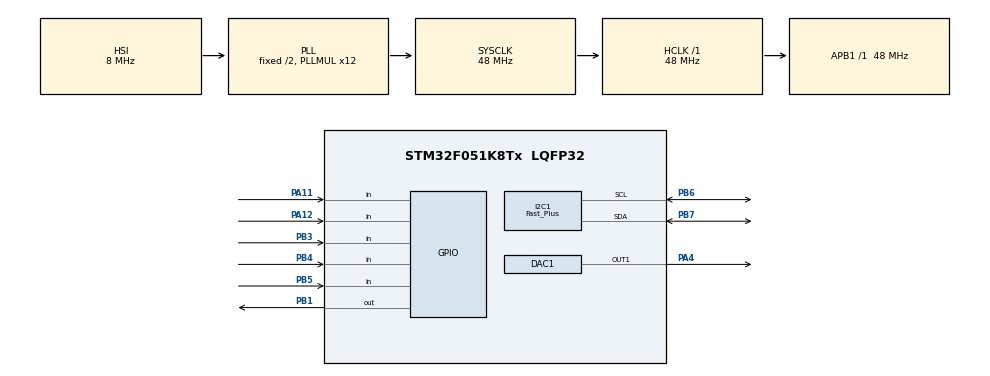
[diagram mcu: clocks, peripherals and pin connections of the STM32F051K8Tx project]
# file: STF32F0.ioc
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DAC1.DAC_Trigger=DAC_TRIGGER_T6_TRGO
Dma.DAC1_CH1.0.Direction=DMA_MEMORY_TO_PERIPH
Dma.DAC1_CH1.0.Instance=DMA1_Channel3
Dma.DAC1_CH1.0.MemDataAlignment=DMA_MDATAALIGN_HALFWORD
Dma.DAC1_CH1.0.MemInc=DMA_MINC_ENABLE
Dma.DAC1_CH1.0.Mode=DMA_CIRCULAR
Dma.DAC1_CH1.0.PeriphDataAlignment=DMA_PDATAALIGN_HALFWORD
Dma.DAC1_CH1.0.PeriphInc=DMA_PINC_DISABLE
Dma.DAC1_CH1.0.Priority=DMA_PRIORITY_LOW
Dma.Request0=DAC1_CH1
I2C1.Analog_Filter=I2C_ANALOGFILTER_DISABLE
I2C1.I2C_Speed_Mode=I2C_Fast_Plus
I2C1.Timing=0x00000002
Mcu.Family=STM32F0
Mcu.Name=STM32F051K8Tx
Mcu.Package=LQFP32
NVIC.DMA1_Channel2_3_IRQn=true\:0\:0\:false\:false\:true\:false\:true
NVIC.TIM14_IRQn=true\:0\:0\:false\:false\:true\:true\:true
NVIC.TIM6_DAC_IRQn=true\:0\:0\:false\:false\:true\:true\:true
PA11.GPIO_PuPd=GPIO_PULLUP
PA11.Signal=GPIO_Input
PA12.GPIO_PuPd=GPIO_PULLUP
PA12.Signal=GPIO_Input
PA13.Mode=Serial_Wire
PA13.Signal=SYS_SWDIO
PA14.Mode=Serial_Wire
PA14.Signal=SYS_SWCLK
PA4.Signal=COMP_DAC11_group
PB1.Signal=GPIO_Output
PB3.GPIO_PuPd=GPIO_PULLUP
PB3.Signal=GPIO_Input
PB4.GPIO_PuPd=GPIO_PULLUP
PB4.Signal=GPIO_Input
PB5.GPIO_PuPd=GPIO_PULLUP
PB5.Signal=GPIO_Input
PB6.GPIO_FM6=SYSCFG_CFGR1_I2C_FMP_PB6
PB6.GPIO_PuPdOD=GPIO_PULLUP
PB6.GPIO_Speed=GPIO_SPEED_FREQ_HIGH
PB6.Mode=I2C
PB6.Signal=I2C1_SCL
PB7.GPIO_FM7=SYSCFG_CFGR1_I2C_FMP_PB7
PB7.Mode=I2C
PB7.Signal=I2C1_SDA
PF0-OSC_IN.Mode=HSE-External-Oscillator
PF0-OSC_IN.Signal=RCC_OSC_IN
PF1-OSC_OUT.Mode=HSE-External-Oscillator
PF1-OSC_OUT.Signal=RCC_OSC_OUT
ProjectManager.HeapSize=0x200
ProjectManager.StackSize=0x400
ProjectManager.TargetToolchain=MDK-ARM V5
RCC.AHBFreq_Value=48000000
RCC.APB1Freq_Value=48000000
RCC.APB1TimFreq_Value=48000000
RCC.HCLKFreq_Value=48000000
RCC.PLLMUL=RCC_PLL_MUL12
RCC.SYSCLKFreq_VALUE=48000000
RCC.SYSCLKSource=RCC_SYSCLKSOURCE_PLLCLK
SH.COMP_DAC11_group.0=DAC1_OUT1,DAC_OUT1
TIM14.Period=1
TIM14.Prescaler=1
TIM6.Period=99
TIM6.TIM_MasterOutputTrigger=TIM_TRGO_UPDATE
VP_TIM14_VS_ClockSourceINT.Mode=Enable_Timer
VP_TIM6_VS_ClockSourceINT.Mode=Enable_Timer
board=custom

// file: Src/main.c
/* USER CODE BEGIN Header */
/**
  ******************************************************************************
  * @file           : main.c
  * @brief          : Main program body
  ******************************************************************************
  * @attention
  *
  * <h2><center>&copy; Copyright (c) 2019 STMicroelectronics.
  * All rights reserved.</center></h2>
  *
  * This software component is licensed by ST under BSD 3-Clause license,
  * the "License"; You may not use this file except in compliance with the
  * License. You may obtain a copy of the License at:
  *                        opensource.org/licenses/BSD-3-Clause
  *
  ******************************************************************************
  */
/* USER CODE END Header */

#include "main.h"

/* USER CODE BEGIN Includes */
#include "ssd1306.h"
#include "oscillator.h"
/* USER CODE END Includes */

DAC_HandleTypeDef hdac1;
DMA_HandleTypeDef hdma_dac1_ch1;

I2C_HandleTypeDef hi2c1;

TIM_HandleTypeDef htim6;
TIM_HandleTypeDef htim14;

/* USER CODE BEGIN PV */
char cfreq[7];
/* USER CODE END PV */

void SystemClock_Config(void);
static void MX_GPIO_Init(void);
static void MX_DMA_Init(void);
static void MX_DAC1_Init(void);
static void MX_I2C1_Init(void);
static void MX_TIM6_Init(void);
static void MX_TIM14_Init(void);

int main(void)
{

  /* MCU Configuration--------------------------------------------------------*/

  /* Reset of all peripherals, Initializes the Flash interface and the Systick. */
  HAL_Init();

  /* Configure the system clock */
  SystemClock_Config();

  /* Initialize all configured peripherals */
  MX_GPIO_Init();
  MX_DMA_Init();
  MX_DAC1_Init();
  MX_I2C1_Init();
  MX_TIM6_Init();
  MX_TIM14_Init();
  /* USER CODE BEGIN 2 */
			DAC_Osc_Init();
			HAL_GPIO_WritePin(GPIOB, GPIO_PIN_1, GPIO_PIN_SET);
			ssd1306_Init();
			ssd1306_Fill(0);
			ssd1306_SetCursor(0 ,0);
			ssd1306_WriteLogo(0);
			ssd1306_UpdateScreen();
			HAL_TIM_Base_Start_IT(&htim14);
  /* USER CODE END 2 */

  /* Infinite loop */
  while (1)
  {

  }
}

void SystemClock_Config(void)
{
  RCC_OscInitTypeDef RCC_OscInitStruct = {0};
  RCC_ClkInitTypeDef RCC_ClkInitStruct = {0};
  RCC_PeriphCLKInitTypeDef PeriphClkInit = {0};

  /** Initializes the CPU, AHB and APB busses clocks
  */
  RCC_OscInitStruct.OscillatorType = RCC_OSCILLATORTYPE_HSI;
  RCC_OscInitStruct.HSIState = RCC_HSI_ON;
  RCC_OscInitStruct.HSICalibrationValue = RCC_HSICALIBRATION_DEFAULT;
  RCC_OscInitStruct.PLL.PLLState = RCC_PLL_ON;
  RCC_OscInitStruct.PLL.PLLSource = RCC_PLLSOURCE_HSI;
  RCC_OscInitStruct.PLL.PLLMUL = RCC_PLL_MUL12;
  RCC_OscInitStruct.PLL.PREDIV = RCC_PREDIV_DIV1;
  if (HAL_RCC_OscConfig(&RCC_OscInitStruct) != HAL_OK)
  {
    Error_Handler();
  }
  /** Initializes the CPU, AHB and APB busses clocks
  */
  RCC_ClkInitStruct.ClockType = RCC_CLOCKTYPE_HCLK|RCC_CLOCKTYPE_SYSCLK
                              |RCC_CLOCKTYPE_PCLK1;
  RCC_ClkInitStruct.SYSCLKSource = RCC_SYSCLKSOURCE_PLLCLK;
  RCC_ClkInitStruct.AHBCLKDivider = RCC_SYSCLK_DIV1;
  RCC_ClkInitStruct.APB1CLKDivider = RCC_HCLK_DIV1;

  if (HAL_RCC_ClockConfig(&RCC_ClkInitStruct, FLASH_LATENCY_1) != HAL_OK)
  {
    Error_Handler();
  }
  PeriphClkInit.PeriphClockSelection = RCC_PERIPHCLK_I2C1;
  PeriphClkInit.I2c1ClockSelection = RCC_I2C1CLKSOURCE_HSI;
  if (HAL_RCCEx_PeriphCLKConfig(&PeriphClkInit) != HAL_OK)
  {
    Error_Handler();
  }
}

static void MX_DAC1_Init(void)
{

  DAC_ChannelConfTypeDef sConfig = {0};

  /** DAC Initialization
  */
  hdac1.Instance = DAC;
  if (HAL_DAC_Init(&hdac1) != HAL_OK)
  {
    Error_Handler();
  }
  /** DAC channel OUT1 config
  */
  sConfig.DAC_Trigger = DAC_TRIGGER_T6_TRGO;
  sConfig.DAC_OutputBuffer = DAC_OUTPUTBUFFER_ENABLE;
  if (HAL_DAC_ConfigChannel(&hdac1, &sConfig, DAC_CHANNEL_1) != HAL_OK)
  {
    Error_Handler();
  }

}

static void MX_I2C1_Init(void)
{

  hi2c1.Instance = I2C1;
  hi2c1.Init.Timing = 0x00000002;
  hi2c1.Init.OwnAddress1 = 0;
  hi2c1.Init.AddressingMode = I2C_ADDRESSINGMODE_7BIT;
  hi2c1.Init.DualAddressMode = I2C_DUALADDRESS_DISABLE;
  hi2c1.Init.OwnAddress2 = 0;
  hi2c1.Init.OwnAddress2Masks = I2C_OA2_NOMASK;
  hi2c1.Init.GeneralCallMode = I2C_GENERALCALL_DISABLE;
  hi2c1.Init.NoStretchMode = I2C_NOSTRETCH_DISABLE;
  if (HAL_I2C_Init(&hi2c1) != HAL_OK)
  {
    Error_Handler();
  }
  /** Configure Analogue filter
  */
  if (HAL_I2CEx_ConfigAnalogFilter(&hi2c1, I2C_ANALOGFILTER_DISABLE) != HAL_OK)
  {
    Error_Handler();
  }
  /** Configure Digital filter
  */
  if (HAL_I2CEx_ConfigDigitalFilter(&hi2c1, 0) != HAL_OK)
  {
    Error_Handler();
  }
  /** I2C Fast mode Plus enable
  */
  __HAL_SYSCFG_FASTMODEPLUS_ENABLE(I2C_FASTMODEPLUS_I2C1);

}

static void MX_TIM6_Init(void)
{

  TIM_MasterConfigTypeDef sMasterConfig = {0};

  htim6.Instance = TIM6;
  htim6.Init.Prescaler = 0;
  htim6.Init.CounterMode = TIM_COUNTERMODE_UP;
  htim6.Init.Period = 99;
  htim6.Init.AutoReloadPreload = TIM_AUTORELOAD_PRELOAD_DISABLE;
  if (HAL_TIM_Base_Init(&htim6) != HAL_OK)
  {
    Error_Handler();
  }
  sMasterConfig.MasterOutputTrigger = TIM_TRGO_UPDATE;
  sMasterConfig.MasterSlaveMode = TIM_MASTERSLAVEMODE_DISABLE;
  if (HAL_TIMEx_MasterConfigSynchronization(&htim6, &sMasterConfig) != HAL_OK)
  {
    Error_Handler();
  }

}

static void MX_TIM14_Init(void)
{

  htim14.Instance = TIM14;
  htim14.Init.Prescaler = 1;
  htim14.Init.CounterMode = TIM_COUNTERMODE_UP;
  htim14.Init.Period = 1;
  htim14.Init.ClockDivision = TIM_CLOCKDIVISION_DIV1;
  htim14.Init.AutoReloadPreload = TIM_AUTORELOAD_PRELOAD_DISABLE;
  if (HAL_TIM_Base_Init(&htim14) != HAL_OK)
  {
    Error_Handler();
  }

}

static void MX_DMA_Init(void)
{
  /* DMA controller clock enable */
  __HAL_RCC_DMA1_CLK_ENABLE();

  /* DMA interrupt init */
  /* DMA1_Channel2_3_IRQn interrupt configuration */
  HAL_NVIC_SetPriority(DMA1_Channel2_3_IRQn, 0, 0);
  HAL_NVIC_EnableIRQ(DMA1_Channel2_3_IRQn);

}

static void MX_GPIO_Init(void)
{
  GPIO_InitTypeDef GPIO_InitStruct = {0};

  /* GPIO Ports Clock Enable */
  __HAL_RCC_GPIOF_CLK_ENABLE();
  __HAL_RCC_GPIOA_CLK_ENABLE();
  __HAL_RCC_GPIOB_CLK_ENABLE();

  /*Configure GPIO pin Output Level */
  HAL_GPIO_WritePin(GPIOB, GPIO_PIN_1, GPIO_PIN_RESET);

  /*Configure GPIO pin : PB1 */
  GPIO_InitStruct.Pin = GPIO_PIN_1;
  GPIO_InitStruct.Mode = GPIO_MODE_OUTPUT_PP;
  GPIO_InitStruct.Pull = GPIO_NOPULL;
  GPIO_InitStruct.Speed = GPIO_SPEED_FREQ_LOW;
  HAL_GPIO_Init(GPIOB, &GPIO_InitStruct);

  /*Configure GPIO pins : PA11 PA12 */
  GPIO_InitStruct.Pin = GPIO_PIN_11|GPIO_PIN_12;
  GPIO_InitStruct.Mode = GPIO_MODE_INPUT;
  GPIO_InitStruct.Pull = GPIO_PULLUP;
  HAL_GPIO_Init(GPIOA, &GPIO_InitStruct);

  /*Configure GPIO pins : PB3 PB4 PB5 */
  GPIO_InitStruct.Pin = GPIO_PIN_3|GPIO_PIN_4|GPIO_PIN_5;
  GPIO_InitStruct.Mode = GPIO_MODE_INPUT;
  GPIO_InitStruct.Pull = GPIO_PULLUP;
  HAL_GPIO_Init(GPIOB, &GPIO_InitStruct);

}

void Error_Handler(void)
{
}

/************************ (C) COPYRIGHT STMicroelectronics *****END OF FILE****/
